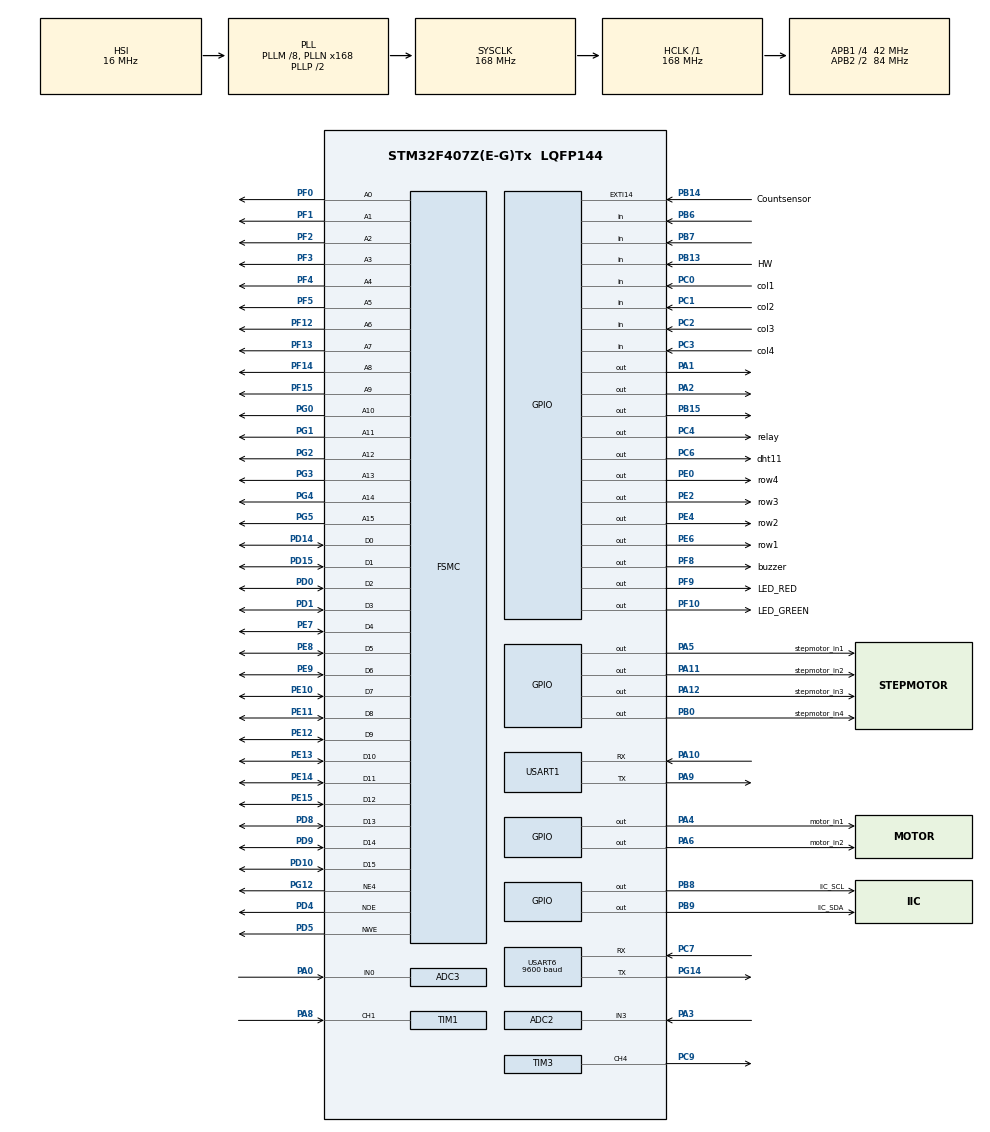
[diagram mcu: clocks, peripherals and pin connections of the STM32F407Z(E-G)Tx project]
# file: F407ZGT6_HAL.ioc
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ADC2.Channel-5\#ChannelRegularConversion=ADC_CHANNEL_3
ADC2.ContinuousConvMode=ENABLE
ADC2.DMAContinuousRequests=ENABLE
ADC2.NbrOfConversionFlag=1
ADC2.Rank-5\#ChannelRegularConversion=1
ADC2.SamplingTime-5\#ChannelRegularConversion=ADC_SAMPLETIME_144CYCLES
ADC3.Channel-0\#ChannelRegularConversion=ADC_CHANNEL_0
ADC3.ContinuousConvMode=ENABLE
ADC3.DMAContinuousRequests=ENABLE
ADC3.InjNumberOfConversion=0
ADC3.NbrOfConversion=1
ADC3.NbrOfConversionFlag=1
ADC3.Rank-0\#ChannelRegularConversion=1
ADC3.SamplingTime-0\#ChannelRegularConversion=ADC_SAMPLETIME_144CYCLES
ADC3.ScanConvMode=DISABLE
Dma.ADC2.1.Direction=DMA_PERIPH_TO_MEMORY
Dma.ADC2.1.FIFOMode=DMA_FIFOMODE_DISABLE
Dma.ADC2.1.Instance=DMA2_Stream2
Dma.ADC2.1.MemDataAlignment=DMA_MDATAALIGN_HALFWORD
Dma.ADC2.1.MemInc=DMA_MINC_ENABLE
Dma.ADC2.1.Mode=DMA_CIRCULAR
Dma.ADC2.1.PeriphDataAlignment=DMA_PDATAALIGN_HALFWORD
Dma.ADC2.1.PeriphInc=DMA_PINC_DISABLE
Dma.ADC2.1.Priority=DMA_PRIORITY_LOW
Dma.ADC3.0.Direction=DMA_PERIPH_TO_MEMORY
Dma.ADC3.0.FIFOMode=DMA_FIFOMODE_DISABLE
Dma.ADC3.0.Instance=DMA2_Stream0
Dma.ADC3.0.MemDataAlignment=DMA_MDATAALIGN_HALFWORD
Dma.ADC3.0.MemInc=DMA_MINC_ENABLE
Dma.ADC3.0.Mode=DMA_CIRCULAR
Dma.ADC3.0.PeriphDataAlignment=DMA_PDATAALIGN_HALFWORD
Dma.ADC3.0.PeriphInc=DMA_PINC_DISABLE
Dma.ADC3.0.Priority=DMA_PRIORITY_LOW
Dma.Request0=ADC3
Dma.Request1=ADC2
FSMC.AddressSetupTime4=1
FSMC.BusTurnAroundDuration4=0
FSMC.DataSetupTime4=15
FSMC.ExtendedAddressSetupTime4=0
FSMC.ExtendedBusTurnAroundDuration4=0
FSMC.ExtendedDataSetupTime4=3
FSMC.ExtendedMode4=FSMC_EXTENDED_MODE_ENABLE
FSMC.WriteOperation4=FSMC_WRITE_OPERATION_ENABLE
Mcu.Family=STM32F4
Mcu.Name=STM32F407Z(E-G)Tx
Mcu.Package=LQFP144
NVIC.DMA2_Stream0_IRQn=true\:0\:0\:false\:false\:true\:false\:true\:true
NVIC.DMA2_Stream2_IRQn=true\:0\:0\:false\:false\:true\:false\:true\:true
NVIC.EXTI15_10_IRQn=true\:0\:0\:false\:false\:true\:true\:true\:true
NVIC.PriorityGroup=NVIC_PRIORITYGROUP_4
NVIC.TIM1_CC_IRQn=true\:0\:0\:false\:false\:true\:true\:true\:true
NVIC.TIM1_UP_TIM10_IRQn=true\:0\:0\:false\:false\:true\:true\:true\:true
NVIC.USART1_IRQn=true\:0\:0\:false\:false\:true\:true\:true\:true
PA0-WKUP.Signal=ADCx_IN0
PA1.GPIO_Speed=GPIO_SPEED_FREQ_HIGH
PA1.Signal=GPIO_Output
PA10.Mode=Asynchronous
PA10.Signal=USART1_RX
PA11.GPIO_Label=stepmotor_in2
PA11.GPIO_Speed=GPIO_SPEED_FREQ_HIGH
PA11.Signal=GPIO_Output
PA12.GPIO_Label=stepmotor_in3
PA12.GPIO_Speed=GPIO_SPEED_FREQ_HIGH
PA12.Signal=GPIO_Output
PA13.Mode=Serial_Wire
PA13.Signal=SYS_JTMS-SWDIO
PA14.Mode=Serial_Wire
PA14.Signal=SYS_JTCK-SWCLK
PA2.GPIO_Speed=GPIO_SPEED_FREQ_HIGH
PA2.Signal=GPIO_Output
PA3.Signal=ADCx_IN3
PA4.GPIO_Label=motor_in1
PA4.GPIO_Speed=GPIO_SPEED_FREQ_HIGH
PA4.Signal=GPIO_Output
PA5.GPIO_Label=stepmotor_in1
PA5.GPIO_Speed=GPIO_SPEED_FREQ_HIGH
PA5.Signal=GPIO_Output
PA6.GPIO_Label=motor_in2
PA6.GPIO_Speed=GPIO_SPEED_FREQ_HIGH
PA6.Signal=GPIO_Output
PA8.Signal=S_TIM1_CH1
PA9.Mode=Asynchronous
PA9.Signal=USART1_TX
PB0.GPIO_Label=stepmotor_in4
PB0.GPIO_Speed=GPIO_SPEED_FREQ_HIGH
PB0.Signal=GPIO_Output
PB10.Signal=USART3_TX
PB11.Signal=USART3_RX
PB13.GPIO_Label=HW
PB13.GPIO_PuPd=GPIO_PULLUP
PB13.Signal=GPIO_Input
PB14.GPIO_Label=Countsensor
PB14.GPIO_ModeDefaultEXTI=GPIO_MODE_IT_FALLING
PB14.GPIO_PuPd=GPIO_PULLUP
PB14.Signal=GPXTI14
PB15.GPIO_Speed=GPIO_SPEED_FREQ_HIGH
PB15.PinState=GPIO_PIN_SET
PB15.Signal=GPIO_Output
PB6.Signal=GPIO_Input
PB7.Signal=GPIO_Input
PB8.GPIO_Label=IIC_SCL
PB8.GPIO_Speed=GPIO_SPEED_FREQ_HIGH
PB8.Signal=GPIO_Output
PB9.GPIO_Label=IIC_SDA
PB9.GPIO_ModeDefaultOutputPP=GPIO_MODE_OUTPUT_OD
PB9.GPIO_PuPd=GPIO_NOPULL
PB9.GPIO_Speed=GPIO_SPEED_FREQ_HIGH
PB9.Signal=GPIO_Output
PC0.GPIO_Label=col1
PC0.GPIO_PuPd=GPIO_PULLDOWN
PC0.Signal=GPIO_Input
PC1.GPIO_Label=col2
PC1.GPIO_PuPd=GPIO_PULLDOWN
PC1.Signal=GPIO_Input
PC14-OSC32_IN.Mode=LSE-External-Oscillator
PC14-OSC32_IN.Signal=RCC_OSC32_IN
PC15-OSC32_OUT.Mode=LSE-External-Oscillator
PC15-OSC32_OUT.Signal=RCC_OSC32_OUT
PC2.GPIO_Label=col3
PC2.GPIO_PuPd=GPIO_PULLDOWN
PC2.Signal=GPIO_Input
PC3.GPIO_Label=col4
PC3.GPIO_PuPd=GPIO_PULLDOWN
PC3.Signal=GPIO_Input
PC4.GPIO_Label=relay
PC4.GPIO_Speed=GPIO_SPEED_FREQ_HIGH
PC4.Signal=GPIO_Output
PC6.GPIO_Label=dht11
PC6.GPIO_Speed=GPIO_SPEED_FREQ_HIGH
PC6.Signal=GPIO_Output
PC7.Mode=Asynchronous
PC7.Signal=USART6_RX
PC9.Signal=S_TIM3_CH4
PD0.Signal=FSMC_D2_DA2
PD1.Signal=FSMC_D3_DA3
PD10.Signal=FSMC_D15_DA15
PD14.Signal=FSMC_D0_DA0
PD15.Signal=FSMC_D1_DA1
PD4.Signal=FSMC_NOE
PD5.Signal=FSMC_NWE
PD8.Signal=FSMC_D13_DA13
PD9.Signal=FSMC_D14_DA14
PE0.GPIO_Label=row4
PE0.GPIO_Speed=GPIO_SPEED_FREQ_HIGH
PE0.Signal=GPIO_Output
PE10.Signal=FSMC_D7_DA7
PE11.Signal=FSMC_D8_DA8
PE12.Signal=FSMC_D9_DA9
PE13.Signal=FSMC_D10_DA10
PE14.Signal=FSMC_D11_DA11
PE15.Signal=FSMC_D12_DA12
PE2.GPIO_Label=row3
PE2.GPIO_Speed=GPIO_SPEED_FREQ_HIGH
PE2.Signal=GPIO_Output
PE4.GPIO_Label=row2
PE4.GPIO_Speed=GPIO_SPEED_FREQ_HIGH
PE4.Signal=GPIO_Output
PE6.GPIO_Label=row1
PE6.GPIO_Speed=GPIO_SPEED_FREQ_HIGH
PE6.Signal=GPIO_Output
PE7.Signal=FSMC_D4_DA4
PE8.Signal=FSMC_D5_DA5
PE9.Signal=FSMC_D6_DA6
PF0.Signal=FSMC_A0
PF1.Signal=FSMC_A1
PF10.GPIO_Label=LED_GREEN
PF10.GPIO_Speed=GPIO_SPEED_FREQ_HIGH
PF10.PinState=GPIO_PIN_SET
PF10.Signal=GPIO_Output
PF12.Signal=FSMC_A6
PF13.Signal=FSMC_A7
PF14.Signal=FSMC_A8
PF15.Signal=FSMC_A9
PF2.Signal=FSMC_A2
PF3.Signal=FSMC_A3
PF4.Signal=FSMC_A4
PF5.Signal=FSMC_A5
PF7.Signal=ADC3_IN5
PF8.GPIO_Label=buzzer
PF8.GPIO_Speed=GPIO_SPEED_FREQ_HIGH
PF8.Signal=GPIO_Output
PF9.GPIO_Label=LED_RED
PF9.GPIO_Speed=GPIO_SPEED_FREQ_HIGH
PF9.PinState=GPIO_PIN_SET
PF9.Signal=GPIO_Output
PG0.Signal=FSMC_A10
PG1.Signal=FSMC_A11
PG12.Mode=NorPsramChipSelect4_4
PG12.Signal=FSMC_NE4
PG14.Mode=Asynchronous
PG14.Signal=USART6_TX
PG2.Signal=FSMC_A12
PG3.Signal=FSMC_A13
PG4.Signal=FSMC_A14
PG5.Signal=FSMC_A15
PH0-OSC_IN.Mode=HSE-External-Oscillator
PH0-OSC_IN.Signal=RCC_OSC_IN
PH1-OSC_OUT.Mode=HSE-External-Oscillator
PH1-OSC_OUT.Signal=RCC_OSC_OUT
ProjectManager.HeapSize=0x200
ProjectManager.StackSize=0x400
ProjectManager.TargetToolchain=MDK-ARM V5.32
RCC.48MHZClocksFreq_Value=84000000
RCC.AHBFreq_Value=168000000
RCC.APB1CLKDivider=RCC_HCLK_DIV4
RCC.APB1Freq_Value=42000000
RCC.APB1TimFreq_Value=84000000
RCC.APB2CLKDivider=RCC_HCLK_DIV2
RCC.APB2Freq_Value=84000000
RCC.APB2TimFreq_Value=168000000
RCC.CortexFreq_Value=168000000
RCC.HCLKFreq_Value=168000000
RCC.HSE_VALUE=25000000
RCC.HSI_VALUE=16000000
RCC.PLLM=8
RCC.PLLN=168
RCC.RCC_RTC_Clock_Source=RCC_RTCCLKSOURCE_LSE
RCC.RCC_RTC_Clock_SourceVirtual=RCC_RTCCLKSOURCE_LSE
RCC.SYSCLKFreq_VALUE=168000000
RCC.SYSCLKSource=RCC_SYSCLKSOURCE_PLLCLK
RCC.VCOOutputFreq_Value=336000000
SH.ADCx_IN0.0=ADC3_IN0,IN0
SH.ADCx_IN3.0=ADC2_IN3,IN3
SH.FSMC_A0.0=FSMC_A0,16b-a4
SH.FSMC_A1.0=FSMC_A1,16b-a4
SH.FSMC_A10.0=FSMC_A10,16b-a4
SH.FSMC_A11.0=FSMC_A11,16b-a4
SH.FSMC_A12.0=FSMC_A12,16b-a4
SH.FSMC_A13.0=FSMC_A13,16b-a4
SH.FSMC_A14.0=FSMC_A14,16b-a4
SH.FSMC_A15.0=FSMC_A15,16b-a4
SH.FSMC_A2.0=FSMC_A2,16b-a4
SH.FSMC_A3.0=FSMC_A3,16b-a4
SH.FSMC_A4.0=FSMC_A4,16b-a4
SH.FSMC_A5.0=FSMC_A5,16b-a4
SH.FSMC_A6.0=FSMC_A6,16b-a4
SH.FSMC_A7.0=FSMC_A7,16b-a4
SH.FSMC_A8.0=FSMC_A8,16b-a4
SH.FSMC_A9.0=FSMC_A9,16b-a4
SH.FSMC_D0_DA0.0=FSMC_D0,16b-d4
SH.FSMC_D10_DA10.0=FSMC_D10,16b-d4
SH.FSMC_D11_DA11.0=FSMC_D11,16b-d4
SH.FSMC_D12_DA12.0=FSMC_D12,16b-d4
SH.FSMC_D13_DA13.0=FSMC_D13,16b-d4
SH.FSMC_D14_DA14.0=FSMC_D14,16b-d4
SH.FSMC_D15_DA15.0=FSMC_D15,16b-d4
SH.FSMC_D1_DA1.0=FSMC_D1,16b-d4
SH.FSMC_D2_DA2.0=FSMC_D2,16b-d4
SH.FSMC_D3_DA3.0=FSMC_D3,16b-d4
SH.FSMC_D4_DA4.0=FSMC_D4,16b-d4
SH.FSMC_D5_DA5.0=FSMC_D5,16b-d4
SH.FSMC_D6_DA6.0=FSMC_D6,16b-d4
SH.FSMC_D7_DA7.0=FSMC_D7,16b-d4
SH.FSMC_D8_DA8.0=FSMC_D8,16b-d4
SH.FSMC_D9_DA9.0=FSMC_D9,16b-d4
SH.FSMC_NOE.0=FSMC_NOE,Sram4
SH.FSMC_NWE.0=FSMC_NWE,Sram4
SH.S_TIM1_CH1.0=TIM1_CH1,Input_Capture1_from_TI1
SH.S_TIM3_CH4.0=TIM3_CH4,PWM Generation4 CH4
TIM1.AutoReloadPreload=TIM_AUTORELOAD_PRELOAD_ENABLE
TIM1.Channel-Input_Capture1_from_TI1=TIM_CHANNEL_1
TIM1.ICFilter_CH1=3
TIM1.Period=9999
TIM1.Prescaler=167
TIM3.AutoReloadPreload=TIM_AUTORELOAD_PRELOAD_ENABLE
TIM3.Channel-PWM\ Generation4\ CH4=TIM_CHANNEL_4
TIM3.Period=49
TIM3.Prescaler=83
USART1.VirtualMode=VM_ASYNC
USART6.BaudRate=9600
USART6.VirtualMode=VM_ASYNC
VP_RTC_VS_RTC_Activate.Mode=RTC_Enabled
VP_TIM1_VS_ClockSourceINT.Mode=Internal
VP_TIM3_VS_ClockSourceINT.Mode=Internal
board=custom

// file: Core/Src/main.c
/* USER CODE BEGIN Header */
/**
  ******************************************************************************
  * @file           : main.c
  * @brief          : Main program body
  ******************************************************************************
  * @attention
  *
  * Copyright (c) 2026 STMicroelectronics.
  * All rights reserved.
  *
  * This software is licensed under terms that can be found in the LICENSE file
  * in the root directory of this software component.
  * If no LICENSE file comes with this software, it is provided AS-IS.
  *
  ******************************************************************************
  */
/* USER CODE END Header */
#include "main.h"
#include "adc.h"
#include "dma.h"
#include "rtc.h"
#include "tim.h"
#include "usart.h"
#include "gpio.h"
#include "fsmc.h"

/* USER CODE BEGIN Includes */
#include "led.h"
#include "Scheduler.h"
#include "delay_us.h"
/* USER CODE END Includes */

void SystemClock_Config(void);

int main(void)
{

  /* MCU Configuration--------------------------------------------------------*/

  /* Reset of all peripherals, Initializes the Flash interface and the Systick. */
  HAL_Init();

  /* Configure the system clock */
  SystemClock_Config();

  /* Initialize all configured peripherals */
  MX_GPIO_Init();
  MX_DMA_Init();
  MX_USART1_UART_Init();
  MX_RTC_Init();
  MX_TIM1_Init();
  MX_ADC3_Init();
  MX_TIM3_Init();
  MX_FSMC_Init();
  MX_ADC2_Init();
  MX_USART6_UART_Init();
  /* USER CODE BEGIN 2 */
  Scheduler_init(); // 任务调度器初始化
  Hardware_init(); // 硬件初始�?
  /* USER CODE END 2 */

  /* Infinite loop */
  /* USER CODE BEGIN WHILE */
  while (1)
  {
	  Scheduler_run();
//	  LED1_ON();
//	  HAL_Delay(200);
//	  LED2_ON();
//	  HAL_Delay(200);
//	  LED1_OFF();
//	  HAL_Delay(200);
//	  LED2_OFF();
//	  HAL_Delay(200);
    /* USER CODE END WHILE */

  }
}

void SystemClock_Config(void)
{
  RCC_OscInitTypeDef RCC_OscInitStruct = {0};
  RCC_ClkInitTypeDef RCC_ClkInitStruct = {0};

  /** Configure the main internal regulator output voltage
  */
  __HAL_RCC_PWR_CLK_ENABLE();
  __HAL_PWR_VOLTAGESCALING_CONFIG(PWR_REGULATOR_VOLTAGE_SCALE1);

  /** Initializes the RCC Oscillators according to the specified parameters
  * in the RCC_OscInitTypeDef structure.
  */
  RCC_OscInitStruct.OscillatorType = RCC_OSCILLATORTYPE_HSI|RCC_OSCILLATORTYPE_LSE;
  RCC_OscInitStruct.LSEState = RCC_LSE_ON;
  RCC_OscInitStruct.HSIState = RCC_HSI_ON;
  RCC_OscInitStruct.HSICalibrationValue = RCC_HSICALIBRATION_DEFAULT;
  RCC_OscInitStruct.PLL.PLLState = RCC_PLL_ON;
  RCC_OscInitStruct.PLL.PLLSource = RCC_PLLSOURCE_HSI;
  RCC_OscInitStruct.PLL.PLLM = 8;
  RCC_OscInitStruct.PLL.PLLN = 168;
  RCC_OscInitStruct.PLL.PLLP = RCC_PLLP_DIV2;
  RCC_OscInitStruct.PLL.PLLQ = 4;
  if (HAL_RCC_OscConfig(&RCC_OscInitStruct) != HAL_OK)
  {
    Error_Handler();
  }

  /** Initializes the CPU, AHB and APB buses clocks
  */
  RCC_ClkInitStruct.ClockType = RCC_CLOCKTYPE_HCLK|RCC_CLOCKTYPE_SYSCLK
                              |RCC_CLOCKTYPE_PCLK1|RCC_CLOCKTYPE_PCLK2;
  RCC_ClkInitStruct.SYSCLKSource = RCC_SYSCLKSOURCE_PLLCLK;
  RCC_ClkInitStruct.AHBCLKDivider = RCC_SYSCLK_DIV1;
  RCC_ClkInitStruct.APB1CLKDivider = RCC_HCLK_DIV4;
  RCC_ClkInitStruct.APB2CLKDivider = RCC_HCLK_DIV2;

  if (HAL_RCC_ClockConfig(&RCC_ClkInitStruct, FLASH_LATENCY_5) != HAL_OK)
  {
    Error_Handler();
  }
}

void Error_Handler(void)
{
  __disable_irq();
  while (1)
  {
  }
}
